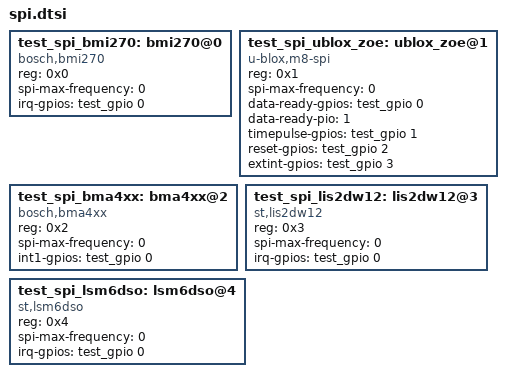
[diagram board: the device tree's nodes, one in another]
/*
 * Copyright (c) 2020, Linaro Ltd.
 *
 * SPDX-License-Identifier: Apache-2.0
 *
 * Application overlay for spi devices
 */

/****************************************
 * PLEASE KEEP REG ADDRESSES SEQUENTIAL *
 ***************************************/

test_spi_bmi270: bmi270@0 {
	compatible = "bosch,bmi270";
	reg = <0x0>;
	spi-max-frequency = <0>;
	irq-gpios = <&test_gpio 0 0>;
};

test_spi_ublox_zoe: ublox_zoe@1 {
	compatible = "u-blox,m8-spi";
	reg = <0x1>;
	spi-max-frequency = <0>;
	data-ready-gpios = <&test_gpio 0 0>;
	data-ready-pio = <1>;
	timepulse-gpios = <&test_gpio 1 0>;
	reset-gpios = <&test_gpio 2 0>;
	extint-gpios = <&test_gpio 3 0>;
};

test_spi_bma4xx: bma4xx@2 {
	compatible = "bosch,bma4xx";
	reg = <0x2>;
	spi-max-frequency = <0>;
	int1-gpios = <&test_gpio 0 0>;
};

test_spi_lis2dw12: lis2dw12@3 {
	compatible = "st,lis2dw12";
	reg = <0x3>;
	spi-max-frequency = <0>;
	irq-gpios = <&test_gpio 0 0>;
};

test_spi_lsm6dso: lsm6dso@4 {
	compatible = "st,lsm6dso";
	reg = <0x4>;
	spi-max-frequency = <0>;
	irq-gpios = <&test_gpio 0 0>;
};
